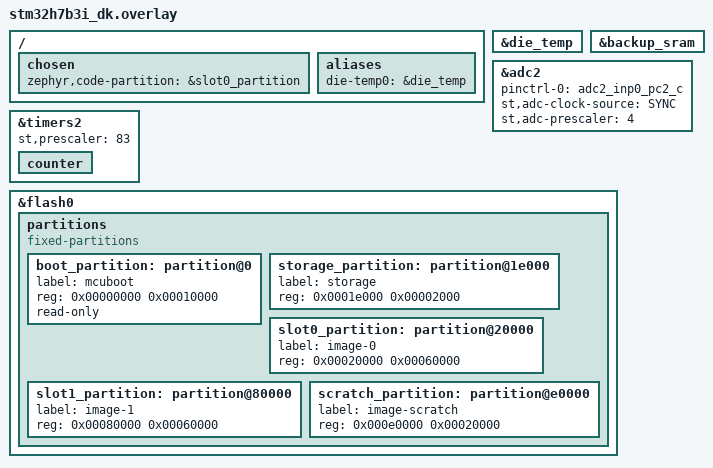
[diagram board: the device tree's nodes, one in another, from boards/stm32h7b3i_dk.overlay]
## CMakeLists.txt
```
# SPDX-License-Identifier: Apache-2.0

# Default board
set(BOARD stm32h7b3i_dk)

cmake_minimum_required(VERSION 3.20.0)

find_package(Zephyr REQUIRED HINTS $ENV{ZEPHYR_BASE})
project(wifi)

FILE(GLOB app_sources src/*.c)
target_sources(app PRIVATE ${app_sources})
zephyr_include_directories(config)
```

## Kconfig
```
# Application Kconfig file
#
# This is loaded when building this directory with west.
menu "Memfault Example Application Configuration"

# Override the MCUBOOT image version to exactly match the version reported
# to Memfault
config MCUBOOT_IMGTOOL_SIGN_VERSION
    default MEMFAULT_BUILTIN_DEVICE_INFO_SOFTWARE_VERSION
endmenu

source "Kconfig.zephyr"
```

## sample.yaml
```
common:
  tags: memfault
  platform_allow: >
    stm32h7b0
sample:
  description: Memfault Example
  name: zephyr-stm32h7b0-example
tests:
  sample.build:
    build_only: true
    # extra_configs:
    #   - CONFIG_MEMFAULT_PROJECT_KEY="dummy"
```

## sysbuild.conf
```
# Sysbuild configuration file.

# Enable MCUboot per default for this sample.
SB_CONFIG_BOOTLOADER_MCUBOOT=y
SB_CONFIG_BOOT_SIGNATURE_TYPE_ECDSA_P256=y
```

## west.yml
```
manifest:
  projects:
    - name: zephyr
      url: https://github.com/zephyrproject-rtos/zephyr
      revision: v3.7.0
      import:
        # Limit the Zephyr modules to the required set
        name-allowlist:
          - cmsis
          - hal_stm32
          - mbedtls
          - mcuboot
          - picolibc

    - name: memfault-firmware-sdk
      url: https://github.com/memfault/memfault-firmware-sdk
      path: modules/lib/memfault-firmware-sdk
      revision: 1.22.0
```

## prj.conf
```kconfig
CONFIG_EARLY_CONSOLE=y
CONFIG_SHELL=y

# Memfault configuration
CONFIG_MEMFAULT=y
CONFIG_MEMFAULT_LOGGING_ENABLE=y
# More verbose Memfault component logs
CONFIG_MEMFAULT_LOG_LEVEL_DBG=y
CONFIG_MEMFAULT_COREDUMP_STACK_SIZE_TO_COLLECT=512

# Don't log printk() statements, they're meant for raw output to the console.
CONFIG_LOG_PRINTK=n

CONFIG_LOG_MODE_IMMEDIATE=y

# Memfault's http client needs a small amount of heap. Zephyr requires a minimum
# heap size for the applied configuration, so select that here to prevent a
# build time message
CONFIG_HEAP_MEM_POOL_SIZE=51200
CONFIG_SYS_HEAP_RUNTIME_STATS=y
CONFIG_SHELL_STACK_SIZE=4096
CONFIG_SYSTEM_WORKQUEUE_STACK_SIZE=2048
CONFIG_MAIN_STACK_SIZE=4096

# hwinfo is used for a unique device id
CONFIG_HWINFO=y

CONFIG_ASSERT=y

# Enable MCUboot
CONFIG_BOOTLOADER_MCUBOOT=y
CONFIG_MCUBOOT_SHELL=y
CONFIG_MCUBOOT_IMG_MANAGER=y
CONFIG_IMG_MANAGER=y
CONFIG_FLASH=y
CONFIG_FLASH_PAGE_LAYOUT=y
CONFIG_FLASH_MAP=y
CONFIG_STREAM_FLASH=y

# For cpu_temp metric
CONFIG_SENSOR=y
CONFIG_ADC=y
```

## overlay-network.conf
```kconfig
CONFIG_NETWORKING=y
# Use the testing RNG. This is NOT suitable for production use. Some devices do
# not have a built-in RNG in Zephyr upstream, so this is convenient for testing.
# CONFIG_TEST_RANDOM_GENERATOR=y

CONFIG_NET_TX_STACK_SIZE=2048
CONFIG_NET_RX_STACK_SIZE=2048

CONFIG_NET_PKT_RX_COUNT=10
CONFIG_NET_PKT_TX_COUNT=10
CONFIG_NET_BUF_RX_COUNT=32
CONFIG_NET_BUF_TX_COUNT=32
CONFIG_NET_BUF_DATA_SIZE=256
CONFIG_NET_DEBUG_NET_PKT_ALLOC=y
CONFIG_MEM_SLAB_TRACE_MAX_UTILIZATION=y

# Network protocols
CONFIG_NET_DHCPV4=y

CONFIG_NET_IPV4=y
CONFIG_NET_IPV6=n

CONFIG_NET_TCP=y

CONFIG_NET_LOG=y
CONFIG_INIT_STACKS=y

CONFIG_NET_SHELL=y

CONFIG_NET_STATISTICS=y
CONFIG_NET_STATISTICS_PERIODIC_OUTPUT=n

CONFIG_WIFI=y
CONFIG_WIFI_LOG_LEVEL_ERR=y
CONFIG_NET_L2_WIFI_SHELL=y

CONFIG_MEMFAULT_HTTP_ENABLE=y
CONFIG_MEMFAULT_HTTP_PERIODIC_UPLOAD=y

# Using the DER format certs saves code and memory. To use PEM instead, swap
# the comments on the following two lines.
CONFIG_MEMFAULT_TLS_CERTS_USE_DER=y
# CONFIG_MBEDTLS_PEM_CERTIFICATE_FORMAT=y

# Additional network configuration for Memfault features
CONFIG_DNS_RESOLVER=y
CONFIG_NET_SOCKETS=y
CONFIG_TLS_CREDENTIALS=y
CONFIG_NET_SOCKETS_SOCKOPT_TLS=y
CONFIG_NET_STATISTICS=y
CONFIG_NET_STATISTICS_USER_API=y

# MbedTLS config
CONFIG_MBEDTLS_SERVER_NAME_INDICATION=y
CONFIG_MBEDTLS_ENABLE_HEAP=y
CONFIG_MBEDTLS_HEAP_SIZE=30000
CONFIG_MBEDTLS_SSL_MAX_CONTENT_LEN=4096
CONFIG_MBEDTLS_MEMORY_DEBUG=y
CONFIG_MBEDTLS_SHELL=y

CONFIG_BASE64=y
CONFIG_TLS_CREDENTIALS_SHELL=y
```

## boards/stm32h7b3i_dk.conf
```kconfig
# Enable backup SRAM for storing reboot reason
CONFIG_STM32_BACKUP_SRAM=y

# Place the reboot reason structure in the backup SRAM output section
CONFIG_MEMFAULT_REBOOT_TRACKING_REGION="BACKUP_SRAM"

CONFIG_COUNTER=y
CONFIG_COUNTER_TIMER_STM32=y

# CONFIG_TASK_WDT=y
```

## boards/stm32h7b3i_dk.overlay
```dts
 / {
	chosen {
		zephyr,code-partition = &slot0_partition;
	};
	aliases {
		die-temp0 = &die_temp;
	};
};

&die_temp {
	status = "okay";
};

/* Enable backup SRAM to store reboot reason through OTA- the location of the
reboot reason structure should be fixed from version to version */
&backup_sram {
	status = "okay";
};

&adc2 {
	pinctrl-0 = <&adc2_inp0_pc2_c>;
	pinctrl-names = "default";
	st,adc-clock-source = <SYNC>;
	st,adc-prescaler = <4>;
	status = "okay";
};

&timers2 {
    status = "okay";
    // pinctrl-0 = <&tim2_ch1_pb10>;
    // pinctrl-names = "default";
    // prescaler = <7999>;
    // counter-mode = "up";
    // enable-interrupt;
	st,prescaler = <83>;

	counter {
		status = "okay";
	};
};

&flash0 {
	partitions {
		compatible = "fixed-partitions";
		#address-cells = <1>;
		#size-cells = <1>;

		boot_partition: partition@0 {
			label = "mcuboot";
			reg = <0x00000000 0x00010000>;
			read-only;
		};
		/*
		 * The flash starting at 0x00010000 and ending at
		 * 0x0001ffff (sectors 16-31) is reserved for use
		 * by the application.
		 */
		storage_partition: partition@1e000 {
			label = "storage";
			reg = <0x0001e000 0x00002000>;
		};
		slot0_partition: partition@20000 {
			label = "image-0";
			reg = <0x00020000 0x00060000>;
		};
		slot1_partition: partition@80000 {
			label = "image-1";
			reg = <0x00080000 0x00060000>;
		};
		scratch_partition: partition@e0000 {
			label = "image-scratch";
			reg = <0x000e0000 0x00020000>;
		};
	};
};
```

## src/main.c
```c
//! @file

#include <string.h>
#include <zephyr/kernel.h>
#include <zephyr/logging/log.h>

#include "app_version.h"
#include "memfault/components.h"
#include "sw_watchdog.h"

// ARM Cortex-M registers for accessing NVIC and vector table
#define SCB_VTOR_ADDR (0xE000ED08U)
#define NVIC_IPR_BASE (0xE000E400U)
#define NVIC_ISER_BASE (0xE000E100U)

LOG_MODULE_REGISTER(mflt_app, LOG_LEVEL_DBG);

// Set up a timer that expires in 1 second.
static void prv_stuck_timer_callback(struct k_timer *dummy) {
  while (1) {
    k_busy_wait(1000 * USEC_PER_MSEC);
  }
}

K_TIMER_DEFINE(s_stuck_timer, prv_stuck_timer_callback, NULL);

static void prv_stuck_timer(void) {
  static uint32_t s_software_watchdog_timeout_ms = 1000;

  k_timer_start(&s_stuck_timer, K_MSEC(s_software_watchdog_timeout_ms),
                K_MSEC(s_software_watchdog_timeout_ms));
}

int main(void) {
  LOG_INF("Memfault Demo App! Board %s\n", CONFIG_BOARD);

  printk("\n" MEMFAULT_BANNER_COLORIZED);
  printk("\nApplication git describe: " STRINGIFY(APP_BUILD_VERSION) "\n");

  // 250ms delay seems to make the logs in the *info_dump() commands work
  // correctly
  k_sleep(K_MSEC(250));

  memfault_device_info_dump();
  memfault_build_info_dump();

  // if coredump is present, dump it
  size_t total_size = 0;
  if (memfault_coredump_has_valid_coredump(&total_size)) {
    LOG_INF("Coredump of size %zu, dumping...", total_size);
    memfault_data_export_dump_chunks();
  }

  sw_watchdog_init();
  prv_stuck_timer();

  // Hack: force systick to a lower priority
  NVIC_SetPriority(SysTick_IRQn, _IRQ_PRIO_OFFSET + 1);

  return 0;
}
```

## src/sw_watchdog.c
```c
//! @file

#include <string.h>
#include <zephyr/kernel.h>
#include <zephyr/logging/log.h>

#include "app_version.h"
#include "memfault/components.h"

LOG_MODULE_REGISTER(swwdg, LOG_LEVEL_DBG);

#include <zephyr/drivers/counter.h>
#include <zephyr/kernel.h>
#include <zephyr/logging/log.h>

#include "memfault/components.h"

#define TIMER_DEV DT_INST(0, st_stm32_counter)
#define WATCHDOG_TIMEOUT_MS 10000

static const struct device *s_sw_watchdog_timer;
struct counter_top_cfg s_sw_watchdog_top_cfg;

static void prv_sw_watchdog_callback(const struct device *dev, void *user_data) {
  ARG_UNUSED(dev);
  ARG_UNUSED(user_data);

  LOG_ERR("Software watchdog expired!");
  MEMFAULT_SOFTWARE_WATCHDOG();
}

void sw_watchdog_feed(void) {
  // To reset the watchdog, we simply reconfigure the top value.
  int err = counter_set_top_value(s_sw_watchdog_timer, &s_sw_watchdog_top_cfg);
  if (err) {
    LOG_ERR("Failed to feed watchdog: %d", err);
  }
}

int sw_watchdog_init(void) {
  int err;
  s_sw_watchdog_timer = DEVICE_DT_GET(TIMER_DEV);
  if (!device_is_ready(s_sw_watchdog_timer)) {
    LOG_ERR("Timer device not ready");
    return -ENODEV;
  }

  s_sw_watchdog_top_cfg = (struct counter_top_cfg){
    .callback = prv_sw_watchdog_callback,
    .user_data = NULL,
    .ticks = counter_us_to_ticks(s_sw_watchdog_timer, WATCHDOG_TIMEOUT_MS * 1000),
    .flags = 0,
  };

  err = counter_start(s_sw_watchdog_timer);
  if (err) {
    LOG_ERR("Failed to start counter: %d", err);
    return err;
  }

  err = counter_set_top_value(s_sw_watchdog_timer, &s_sw_watchdog_top_cfg);
  if (err) {
    LOG_ERR("Failed to set top value: %d", err);
    return err;
  }

  return 0;
}
```

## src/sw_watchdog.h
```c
//! @file

#pragma once

void sw_watchdog_feed(void);
int sw_watchdog_init(void);
```
